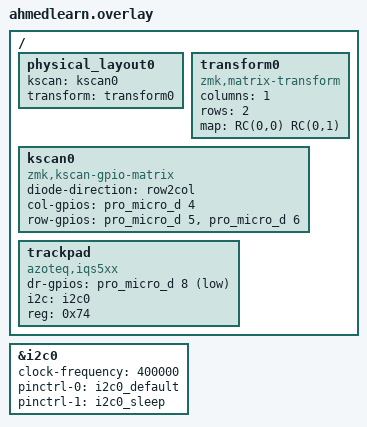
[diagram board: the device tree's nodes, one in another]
#include <dt-bindings/zmk/matrix_transform.h>
#include "ahmedlearn.dtsi"

/ {

    physical_layout0 {
        kscan = <&kscan0>;
        transform = <&transform0>;
        };

     transform0: transform0 {
        compatible = "zmk,matrix-transform";
        columns = <1>; // Length of the "col-gpios" array
        rows = <2>; // Length of the "row-gpios" array
        map = <
        //   Key 1 | Key 2
            RC(0,0) RC(0,1)
        >;
    };

      kscan0: kscan0 {
        compatible = "zmk,kscan-gpio-matrix";
        diode-direction = "row2col";

        col-gpios
            = <&pro_micro_d 4 GPIO_ACTIVE_HIGH>
            ;

        row-gpios
            = <&pro_micro_d 5 (GPIO_ACTIVE_HIGH | GPIO_PULL_DOWN)>
            , <&pro_micro_d 6 (GPIO_ACTIVE_HIGH | GPIO_PULL_DOWN)>
            ;
    };

    trackpad {
        compatible = "azoteq,iqs5xx";
        status = "okay";
        
        dr-gpios = <&pro_micro_d 8 GPIO_ACTIVE_LOW>;  // Change pin number as needed
        
        i2c = <&i2c0>;
        reg = <0x74>;  // I2C address of IQS5XX
    };
};

&i2c0 {
    status = "okay";
    
    clock-frequency = <400000>;
    
    pinctrl-0 = <&i2c0_default>;
    pinctrl-1 = <&i2c0_sleep>;
    pinctrl-names = "default", "sleep";
};
